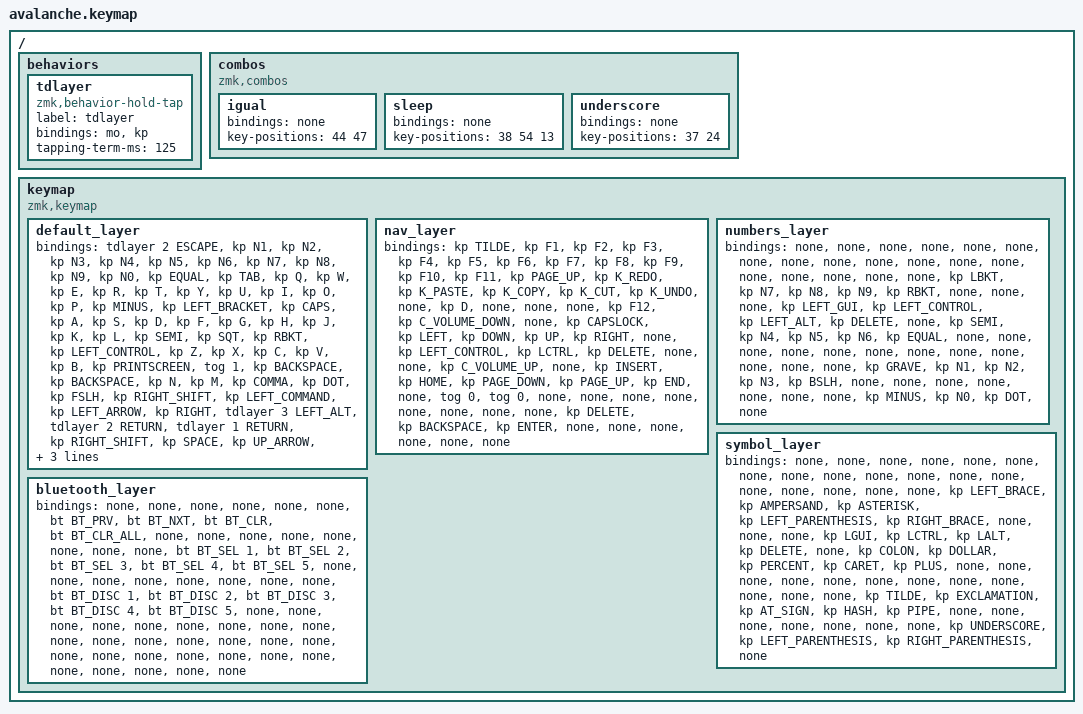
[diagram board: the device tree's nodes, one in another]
#include <behaviors.dtsi>
#include <dt-bindings/zmk/bt.h>
#include <dt-bindings/zmk/keys.h>

/ {
    behaviors {
        tdlayer: tdlayer {
            compatible = "zmk,behavior-hold-tap";
            #binding-cells = <2>;
            label = "tdlayer";
            bindings = <&mo>, <&kp>;

            tapping-term-ms = <125>;
        };
    };

    combos {
        compatible = "zmk,combos";

        igual {
            bindings = <&none>;
            key-positions = <44 47>;
        };

        sleep {
            bindings = <&none>;
            key-positions = <38 54 13>;
        };

        underscore {
            bindings = <&none>;
            key-positions = <37 24>;
        };
    };

    keymap {
        compatible = "zmk,keymap";

        /*
        &none  &none  &none  &none  &none  &none                                   &none  &none  &none  &none  &none  &none 
// ------------------------------------------------------------------------------------------------------------------------------------------------------------------------------------
        &none  &none  &none  &none  &none  &none                                   &none  &none  &none  &none  &none  &none 
// ------------------------------------------------------------------------------------------------------------------------------------------------------------------------------------
&none  &none  &none  &none  &none  &none  &none                                   &none  &none  &none  &none  &none  &none  &none 
// ------------------------------------------------------------------------------------------------------------------------------------------------------------------------------------
        &none  &none  &none  &none  &none  &none  &none  &none    &none &none  &none  &none  &none  &none  &none  &none 
// ------------------------------------------------------------------------------------------------------------------------------------------------------------------------------------
                                &none  &none  &none  &none  &none    &none &none  &none  &none  &none
*/

        default_layer {
            bindings = <
&tdlayer 2 ESCAPE  &kp N1  &kp N2  &kp N3  &kp N4  &kp N5  &kp N6  &kp N7  &kp N8  &kp N9  &kp N0  &kp EQUAL  &kp TAB  &kp Q  &kp W  &kp E  &kp R  &kp T  &kp Y  &kp U  &kp I  &kp O  &kp P  &kp MINUS  &kp LEFT_BRACKET  &kp CAPS  &kp A  &kp S  &kp D  &kp F  &kp G  &kp H  &kp J  &kp K  &kp L  &kp SEMI  &kp SQT  &kp RBKT  &kp LEFT_CONTROL  &kp Z  &kp X  &kp C  &kp V  &kp B  &kp PRINTSCREEN  &tog 1  &kp BACKSPACE  &kp BACKSPACE  &kp N  &kp M  &kp COMMA  &kp DOT  &kp FSLH  &kp RIGHT_SHIFT  &kp LEFT_COMMAND  &kp LEFT_ARROW  &kp RIGHT  &tdlayer 3 LEFT_ALT  &tdlayer 2 RETURN  &tdlayer 1 RETURN  &kp RIGHT_SHIFT  &kp SPACE  &kp UP_ARROW  &kp DOWN
            >;

            sensor-bindings = <&inc_dec_kp C_VOL_UP C_VOL_DN &inc_dec_kp PG_UP PG_DN>;
        };

        nav_layer {
            bindings = <
&kp TILDE  &kp F1  &kp F2  &kp F3  &kp F4  &kp F5  &kp F6  &kp F7  &kp F8  &kp F9  &kp F10  &kp F11  &kp PAGE_UP  &kp K_REDO  &kp K_PASTE  &kp K_COPY  &kp K_CUT  &kp K_UNDO  &none  &kp D  &none  &none  &none  &kp F12  &kp C_VOLUME_DOWN  &none  &kp CAPSLOCK  &kp LEFT  &kp DOWN  &kp UP  &kp RIGHT  &none  &kp LEFT_CONTROL  &kp LCTRL  &kp DELETE  &none  &none  &kp C_VOLUME_UP  &none  &kp INSERT  &kp HOME  &kp PAGE_DOWN  &kp PAGE_UP  &kp END  &none  &tog 0  &tog 0  &none  &none  &none  &none  &none  &none  &none  &none  &kp DELETE  &kp BACKSPACE  &kp ENTER  &none  &none  &none  &none  &none  &none
            >;
        };

        numbers_layer {
            bindings = <
&none  &none  &none  &none  &none  &none  &none  &none  &none  &none  &none  &none  &none  &none  &none  &none  &none  &none  &kp LBKT  &kp N7  &kp N8  &kp N9  &kp RBKT  &none  &none  &none  &kp LEFT_GUI  &kp LEFT_CONTROL  &kp LEFT_ALT  &kp DELETE  &none  &kp SEMI  &kp N4  &kp N5  &kp N6  &kp EQUAL  &none  &none  &none  &none  &none  &none  &none  &none  &none  &none  &none  &none  &kp GRAVE  &kp N1  &kp N2  &kp N3  &kp BSLH  &none  &none  &none  &none  &none  &none  &none  &kp MINUS  &kp N0  &kp DOT  &none
            >;
        };

        symbol_layer {
            bindings = <
&none  &none  &none  &none  &none  &none  &none  &none  &none  &none  &none  &none  &none  &none  &none  &none  &none  &none  &kp LEFT_BRACE  &kp AMPERSAND  &kp ASTERISK  &kp LEFT_PARENTHESIS  &kp RIGHT_BRACE  &none  &none  &none  &kp LGUI  &kp LCTRL  &kp LALT  &kp DELETE  &none  &kp COLON  &kp DOLLAR  &kp PERCENT  &kp CARET  &kp PLUS  &none  &none  &none  &none  &none  &none  &none  &none  &none  &none  &none  &none  &kp TILDE  &kp EXCLAMATION  &kp AT_SIGN  &kp HASH  &kp PIPE  &none  &none  &none  &none  &none  &none  &none  &kp UNDERSCORE  &kp LEFT_PARENTHESIS  &kp RIGHT_PARENTHESIS  &none
            >;
        };

        bluetooth_layer {
            bindings = <
&none  &none  &none  &none  &none  &none  &bt BT_PRV  &bt BT_NXT  &bt BT_CLR  &bt BT_CLR_ALL  &none  &none  &none  &none  &none  &none  &none  &none  &bt BT_SEL 1  &bt BT_SEL 2  &bt BT_SEL 3  &bt BT_SEL 4  &bt BT_SEL 5  &none  &none  &none  &none  &none  &none  &none  &none  &bt BT_DISC 1  &bt BT_DISC 2  &bt BT_DISC 3  &bt BT_DISC 4  &bt BT_DISC 5  &none  &none  &none  &none  &none  &none  &none  &none  &none  &none  &none  &none  &none  &none  &none  &none  &none  &none  &none  &none  &none  &none  &none  &none  &none  &none  &none  &none
            >;
        };
    };
};
